VERSION ""

NS_ :

BS_:

BU_: TRUSTIA_L4_CORE MIFA7_EPS MIFA7_IPB MIFA7_MCU CGW_GATEWAY

BO_ 416 MIFA7_STEERING_CMD: 16 TRUSTIA_L4_CORE
 SG_ STEER_TARGET_ANGLE : 0|16@1- (0.01,0) [-35|35] "deg" MIFA7_EPS
 SG_ STEER_TARGET_RATE : 16|16@1+ (0.1,0) [0|500] "deg/s" MIFA7_EPS
 SG_ STEER_MAX_TORQUE : 32|16@1+ (0.01,0) [0|6] "Nm" MIFA7_EPS
 SG_ STEER_CONTROL_MODE : 48|4@1+ (1,0) [0|3] "" MIFA7_EPS
 SG_ STEER_ROLLING_COUNTER : 52|4@1+ (1,0) [0|15] "" MIFA7_EPS
 SG_ STEER_CHECKSUM : 56|8@1+ (1,0) [0|255] "" MIFA7_EPS

BO_ 417 MIFA7_ACCEL_BRAKE_CMD: 16 TRUSTIA_L4_CORE
 SG_ TARGET_ACCEL : 0|16@1- (0.01,0) [-6.5|2.5] "m/s2" MIFA7_IPB,MIFA7_MCU
 SG_ TARGET_SPEED : 16|16@1+ (0.01,0) [0|20] "m/s" MIFA7_MCU
 SG_ TARGET_BRAKE_PRESSURE : 32|16@1+ (0.1,0) [0|150] "bar" MIFA7_IPB
 SG_ DRIVE_CONTROL_MODE : 48|4@1+ (1,0) [0|3] "" MIFA7_IPB
 SG_ DRIVE_ROLLING_COUNTER : 52|4@1+ (1,0) [0|15] "" MIFA7_IPB
 SG_ DRIVE_CHECKSUM : 56|8@1+ (1,0) [0|255] "" MIFA7_IPB

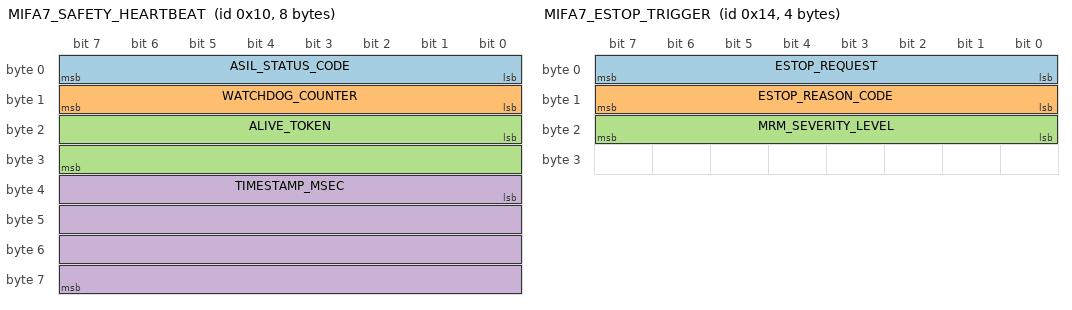
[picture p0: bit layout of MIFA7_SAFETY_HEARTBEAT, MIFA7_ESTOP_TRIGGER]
BO_ 16 MIFA7_SAFETY_HEARTBEAT: 8 TRUSTIA_L4_CORE
 SG_ ASIL_STATUS_CODE : 0|8@1+ (1,0) [0|255] "" MIFA7_EPS,MIFA7_IPB
 SG_ WATCHDOG_COUNTER : 8|8@1+ (1,0) [0|15] "" MIFA7_EPS,MIFA7_IPB
 SG_ ALIVE_TOKEN : 16|16@1+ (1,0) [0|65535] "" MIFA7_EPS,MIFA7_IPB
 SG_ TIMESTAMP_MSEC : 32|32@1+ (1,0) [0|4294967295] "ms" MIFA7_EPS,MIFA7_IPB

BO_ 20 MIFA7_ESTOP_TRIGGER: 4 TRUSTIA_L4_CORE
 SG_ ESTOP_REQUEST : 0|8@1+ (1,0) [0|255] "" MIFA7_IPB
 SG_ ESTOP_REASON_CODE : 8|8@1+ (1,0) [0|255] "" MIFA7_IPB
 SG_ MRM_SEVERITY_LEVEL : 16|8@1+ (1,0) [0|5] "" MIFA7_IPB

BO_ 902 MIFA7_WHEEL_TELEMETRY: 16 CGW_GATEWAY
 SG_ WHEEL_SPEED_FL : 0|16@1+ (0.01,0) [0|250] "km/h" TRUSTIA_L4_CORE
 SG_ WHEEL_SPEED_FR : 16|16@1+ (0.01,0) [0|250] "km/h" TRUSTIA_L4_CORE
 SG_ WHEEL_SPEED_RL : 32|16@1+ (0.01,0) [0|250] "km/h" TRUSTIA_L4_CORE
 SG_ WHEEL_SPEED_RR : 48|16@1+ (0.01,0) [0|250] "km/h" TRUSTIA_L4_CORE

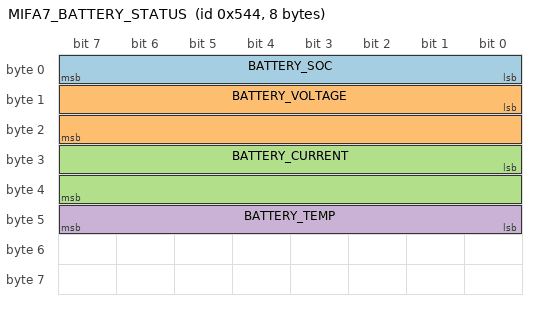
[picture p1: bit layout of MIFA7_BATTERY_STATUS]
BO_ 1348 MIFA7_BATTERY_STATUS: 8 CGW_GATEWAY
 SG_ BATTERY_SOC : 0|8@1+ (0.5,0) [0|100] "%" TRUSTIA_L4_CORE
 SG_ BATTERY_VOLTAGE : 8|16@1+ (0.1,0) [0|1000] "V" TRUSTIA_L4_CORE
 SG_ BATTERY_CURRENT : 24|16@1- (0.1,0) [-1000|1000] "A" TRUSTIA_L4_CORE
 SG_ BATTERY_TEMP : 40|8@1+ (1,-40) [-40|120] "degC" TRUSTIA_L4_CORE

CM_ BO_ 416 "SAIC Maxus MIFA 7 EPS Steering Actuation CAN-FD Message (100 Hz)";
CM_ BO_ 417 "SAIC Maxus MIFA 7 IPB Decoupled Braking & MCU Drive Torque CAN-FD Message (50 Hz)";
CM_ BO_ 16 "ISO 26262 ASIL-D 50ms Watchdog Heartbeat Bus Command";
CM_ BO_ 20 "Minimal Risk Maneuver (MRM) Safe Stop & EPB Brake Lockup Message";
CM_ BO_ 902 "Chassis Wheel Speed Sensors Telemetry Broadcast";
CM_ BO_ 1348 "High Voltage Traction Battery SoC and Electrical Telemetry Broadcast";
